# MSS_RCM_MSS_RCM_53208000h register map
Vendor: Texas Instruments
Registers are 32-bit, read-write, reset 0x0 unless marked. A register's access mark holds for its fields unless they carry their own. Offsets are as the file gives them; [hi:lo] are bit positions; {n}, {i} and the like mark numbered series.

## MSS_RCM (part 2 of 2)
0x10 MSS_RCM_R5SS0_RST_STATUS ro reset 0x3 — R5SS Reset Cause Status register of corresponding R5SS.
  [10:0] R5SS0_RST_STATUS_CAUSE — Has the status because of which reset has happened. Bit0: POR ResetBit1: Warm Reset [ALso set during POR Reset]Bit2: CR5SS0 STC ResetBit3 Reset for CORE0 and MSS_CORE00_VIM using MSS_RCM::MSS_CR5SSA0_RST_CTRLBit4: Reset for CORE1 and MSS_CORE10_VIM using MSS_RCM::MSS_CR5SSB0_RST_CTRLBit5: Reset for CORE0 only using MSS_RCM::MSS_CORE00_RST_CTRLBit6: Reset for CORE1 only using using MSS_RCM::MSS_CORE10_RST_CTRLBit7: Reset for CORE0 and MSS_CORE00_VIM caused because of reset request by debugger in CORE00 Bit8: Reset for CORE10 and MSS_CORE10_VIM caused because of reset request by debugger in CORE10Bit9: Reset for CR5SS0 by the RESET FSM using MSS_CTRL::R5SS0_CONTROL_RESET_FSM_TRIGGER Bit10 : Reset for CR5SS0 using MSS_RCM.R5SS0_POR_RST_CTRL
0x20 MSS_RCM_R5SS0_RST_CAUSE_CLR — R5SS Reset Cause Clear register of corresponding R5SS.
  [2:0] R5SS0_RST_CAUSE_CLR_CLR — Has the status because of which reset has happened. Bit0: POR ResetBit1: Warm Reset [ALso set during POR Reset]Bit2: CR5SS1 STC ResetBit3 Reset for CORE0 and MSS_CORE00_VIM using MSS_RCM::MSS_CR5SSA0_RST_CTRLBit4: Reset for CORE1 and MSS_CORE10_VIM using MSS_RCM::MSS_CR5SSB0_RST_CTRLBit5: Reset for CORE0 only using MSS_RCM::MSS_CORE00_RST_CTRLBit6: Reset for CORE1 only using using MSS_RCM::MSS_CORE10_RST_CTRLBit7: Reset for CORE0 and MSS_CORE00_VIM caused because of reset request by debugger in CORE00 Bit8: Reset for CORE10 and MSS_CORE10_VIM caused because of reset request by debugger in CORE10Bit9: Reset for CR5SS0 by the RESET FSM using MSS_CTRL::R5SS0_CONTROL_RESET_FSM_TRIGGER Bit10 : Reset for CR5SS1 using MSS_RCM.R5SS0_POR_RST_CTRL
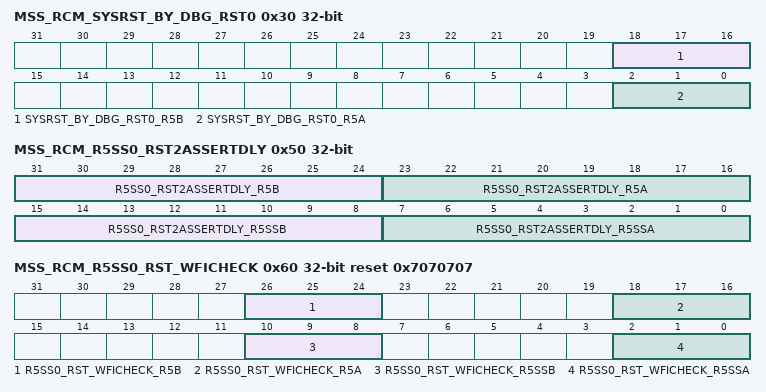
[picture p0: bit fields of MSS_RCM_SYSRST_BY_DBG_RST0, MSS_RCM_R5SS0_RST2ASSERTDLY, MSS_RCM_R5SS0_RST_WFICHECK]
0x30 MSS_RCM_SYSRST_BY_DBG_RST0 — This register enables Core debug reset request to propogate to RCM.
  [18:16] SYSRST_BY_DBG_RST0_R5B — Writing 3'b111 will block debug reset request from CORE1 toggling reset for CORE1 of respective R5SS
  [2:0] SYSRST_BY_DBG_RST0_R5A — Writing 3'b111 will block debug reset request from CORE0 toggling reset for CORE0 of respective R5SS
0x40 MSS_RCM_RST_ASSERDLY0 reset 0xF — This register controls the reset duration of the corrseponding R5SS.
  [7:0] RST_ASSERDLY0_COMMON — Value decides number of cycles reset should be kept asserted for CR5SS related resets. Programming a value of 0xFF will keep the reset asserted untill a new value other than 0xFF is written to this registerThe actual duration is count + 2 cycles. S/W Recommended value for this is 0x0FThe COUNT is applicable to both CPU cores
0x50 MSS_RCM_R5SS0_RST2ASSERTDLY — This register controls the delay of Reset assertion to the corresponding R5SS.
  [31:24] R5SS0_RST2ASSERTDLY_R5B — Value decides number of cycles to wait before asserting reset for local reset for CORE1
  [23:16] R5SS0_RST2ASSERTDLY_R5A — Value decides number of cycles to wait before asserting reset for local reset for CORE0.
  [15:8] R5SS0_RST2ASSERTDLY_R5SSB — Value decides number of cycles to wait before asserting reset for global reset for CORE1
  [7:0] R5SS0_RST2ASSERTDLY_R5SSA — Value decides number of cycles to wait before asserting reset for global reset for CORE0.
0x60 MSS_RCM_R5SS0_RST_WFICHECK reset 0x7070707 — Enable WFI ceck before R5 Reset is asserted.
  [26:24] R5SS0_RST_WFICHECK_R5B — Writing 3'b000 will disable check for WFI before local reset assertion of CORE0
  [18:16] R5SS0_RST_WFICHECK_R5A — Writing 3'b000 will disable check for WFI before local reset assertion of CORE0
  [10:8] R5SS0_RST_WFICHECK_R5SSB — Writing 3'b000 will disable check for WFI before global reset assertion of CORE1
  [2:0] R5SS0_RST_WFICHECK_R5SSA — Writing 3'b000 will disable check for WFI before global reset assertion of CORE0
0x100 MSS_RCM_MCAN0_CLK_SRC_SEL — Clock Source selection Register for corresponding Root clock.
  [11:0] MCAN0_CLK_SRC_SEL_CLKSRCSEL — Select line for selecting source clock for QSPI.Data should be loaded as multibit. For example: if '0x5' should be selected then '0x555' should be configured to the register. Use the following values for selecting clock source-0x000 - WUCPUCLK0x111 - EXT_REFCLK0x222 - SYS_CLK0x333 - DPLL_PER_HSDIV0_CLKOUT10x444 - DPLL_CORE_HSDIV0_CLKOUT00x555 - RCCLK10M0x666 - XTALCLK0x777 - RCCLK10M
0x104 MSS_RCM_MCAN1_CLK_SRC_SEL — Clock Source selection Register for corresponding Root clock.
  [11:0] MCAN1_CLK_SRC_SEL_CLKSRCSEL — Select line for selecting source clock for QSPI.Data should be loaded as multibit. For example: if '0x5' should be selected then '0x555' should be configured to the register. Use the following values for selecting clock source-0x000 - WUCPUCLK0x111 - EXT_REFCLK0x222 - SYS_CLK0x333 - DPLL_PER_HSDIV0_CLKOUT10x444 - DPLL_CORE_HSDIV0_CLKOUT00x555 - RCCLK10M0x666 - XTALCLK0x777 - RCCLK10M
{0x140+4i} MSS_RCM_RTI{i}_CLK_SRC_SEL (i=0..3)
  [11:0] RTI{i}_CLK_SRC_SEL_CLKSRCSEL — Select line for selecting source clock for Corresponding RTI.Data should be loaded as multibit. For example: if '0x5' should be selected then '0x555' should be configured to the register. Use the following values to select clk src- 0x000 - WUCPUCLK0x111 - EXT_REFCLK0x222 - SYS_CLK0x333 - DPLL_PER_HSDIV0_CLKOUT00x444 - DPLL_CORE_HSDIV0_CLKOUT10x555 - RCCLK10M0x666 - DPLL_ETH_HSDIV0_CLKOUT00x777 - CTPS_GENF0
{0x180+4i} MSS_RCM_MCSPI{i}_CLK_SRC_SEL (i=0..3)
  [11:0] MCSPI{i}_CLK_SRC_SEL_CLKSRCSEL — Select line for selecting source clock for Corresponding SPI.Data should be loaded as multibit. For example: if '0x5' should be selected then '0x555' should be configured to the register.Use the following values to select clk src-0x000 - WUCPUCLK0x111 - EXT_REFCLK0x222 - SYS_CLK0x333 - DPLL_PER_HSDIV0_CLKOUT00x444 - DPLL_CORE_HSDIV0_CLKOUT00x555 - RCCLK10M0x666 - XTALCLK0x777 - RCCLK10M
0x1C0 MSS_RCM_WDT0_CLK_SRC_SEL
  [11:0] WDT0_CLK_SRC_SEL_CLKSRCSEL — Select line for selecting source clock for WDT.Data should be loaded as multibit. For example: if '0x5' should be selected then '0x555' should be configured to the register.Use the following values to select clk src-0x000 - WUCPUCLK0x111 - RCCLK10M0x222 - SYS_CLK0x333 - DPLL_PER_HSDIV0_CLKOUT00x444 - DPLL_CORE_HSDIV0_CLKOUT10x555 - RCCLK10M0x666 - XTALCLK0x777 - RCCLK32K
0x1C4 MSS_RCM_WDT1_CLK_SRC_SEL
  [11:0] WDT1_CLK_SRC_SEL_CLKSRCSEL — Select line for selecting source clock for WDT.Data should be loaded as multibit. For example: if '0x5' should be selected then '0x555' should be configured to the register.Use the following values to select clk src-0x000 - WUCPUCLK0x111 - RCCLK10M0x222 - SYS_CLK0x333 - DPLL_PER_HSDIV0_CLKOUT00x444 - DPLL_CORE_HSDIV0_CLKOUT10x555 - RCCLK10M0x666 - XTALCLK0x777 - RCCLK32K
0x1E0 MSS_RCM_PRU_ICSS0_UART0_CLK_SRC_SEL
  [11:0] PRU_ICSS0_UART0_CLK_SRC_SEL_CLKSRCSEL — Select line for selecting source clock for ICSSM0_UCLK.Data should be loaded as multibit. For example: if '0x5' should be selected then '0x555' should be configured to the register.Use the following values to select clk src-0x000 - WUCPUCLK0x111 - EXT_REFCLK0x222 - SYS_CLK0x333 - DPLL_PER_HSDIV0_CLKOUT00x444 - DPLL_CORE_HSDIV0_CLKOUT00x555 - RCCLK10M0x666 - XTALCLK0x777 - DPLL_PER_HSDIV0_CLKOUT2
0x1E4 MSS_RCM_PRU_ICSS1_UART0_CLK_SRC_SEL
  [11:0] PRU_ICSS1_UART0_CLK_SRC_SEL_CLKSRCSEL — Select line for selecting source clock for ICSSM0_UCLK.Data should be loaded as multibit. For example: if '0x5' should be selected then '0x555' should be configured to the register.Use the following values to select clk src-0x000 - WUCPUCLK0x111 - EXT_REFCLK0x222 - SYS_CLK0x333 - DPLL_PER_HSDIV0_CLKOUT00x444 - DPLL_CORE_HSDIV0_CLKOUT00x555 - RCCLK10M0x666 - XTALCLK0x777 - DPLL_PER_HSDIV0_CLKOUT2
0x1F0 MSS_RCM_OSPI0_CLK_SRC_SEL
  [11:0] OSPI0_CLK_SRC_SEL_CLKSRCSEL — Select line for selecting source clock for OSPI.Data should be loaded as multibit. For example: if '0x5' should be selected then '0x555' should be configured to the register.Use the following values to select clk src-0x000 - WUCPUCLK0x111 - EXT_REFCLK0x222 - SYS_CLK0x333 - DPLL_PER_HSDIV0_CLKOUT00x444 - DPLL_ETH_HSDIV0_CLKOUT20x555 - RCCLK10M0x666 - DPLL_CORE_HSDIV0_CLKOUT30x777 - DPLL_PER_HSDIV0_CLKOUT3
0x1F4 MSS_RCM_OSPI1_CLK_SRC_SEL
  [11:0] OSPI1_CLK_SRC_SEL_CLKSRCSEL — Select line for selecting source clock for OSPI.Data should be loaded as multibit. For example: if '0x5' should be selected then '0x555' should be configured to the register.Use the following values to select clk src-0x000 - WUCPUCLK0x111 - EXT_REFCLK0x222 - SYS_CLK0x333 - DPLL_PER_HSDIV0_CLKOUT00x444 - DPLL_ETH_HSDIV0_CLKOUT20x555 - RCCLK10M0x666 - DPLL_CORE_HSDIV0_CLKOUT30x777 - DPLL_PER_HSDIV0_CLKOUT3
0x1F8 MSS_RCM_CONTROLSS_PLL_CLK_SRC_SEL
  [11:0] CONTROLSS_PLL_CLK_SRC_SEL_CLKSRCSEL — Select line for selecting source clock for CONTROLSS_PLL.Data should be loaded as multibit. For example: if '0x5' should be selected then '0x555' should be configured to the register.Use the following values to select clk src-0x000 - WUCPUCLK0x111 - EXT_REFCLK0x222 - DPLL_CORE_HSDIV0_CLKOUT20x333 - DPLL_PER_HSDIV0_CLKOUT00x444 - DPLL_CORE_HSDIV0_CLKOUT00x555 - RCCLK10M0x666 - XTALCLK0x777 - RCCLK10M
0x1FC MSS_RCM_CPTS_CLK_SRC_SEL
  [11:0] CPTS_CLK_SRC_SEL_CLKSRCSEL — Select line for selecting source clock for CPTS.Data should be loaded as multibit. For example: if '0x5' should be selected then '0x555' should be configured to the register.Use the following values to select clk src-0x000 - WUCPUCLK0x111 - EXT_REFCLK0x222 - SYS_CLK0x333 - DPLL_CORE_HSDIV0_CLKOUT10x444 - DPLL_ETH_HSDIV0_CLKOUT00x555 - RCCLK10M0x666 - XTALCLK0x777 - DPLL_PER_HSDIV0_CLKOUT1
0x200 MSS_RCM_GPMC_CLK_SRC_SEL
  [11:0] GPMC_CLK_SRC_SEL_CLKSRCSEL — Select line for selecting source clock for GPMC. Data should be loaded as multibit. For example: if '0x5' should be selected then '0x555' should be configured to the register.Use the following values to select clk src-0x000 - WUCPUCLK0x111 - EXT_REFCLK0x222 - SYS_CLK0x333 - DPLL_PER_HSDIV0_CLKOUT00x444 - DPLL_CORE_HSDIV0_CLKOUT00x555 - RCCLK10M0x666 - XTALCLK0x777 - RCCLK10M
0x204 MSS_RCM_MMC0_CLK_SRC_SEL
  [11:0] MMC0_CLK_SRC_SEL_CLKSRCSEL — Select line for selecting source clock for MMCSD.Data should be loaded as multibit. For example: if '0x5' should be selected then '0x555' should be configured to the register.Use the following values to select clk src-0x000 - WUCPUCLK0x111 - EXT_REFCLK0x222 - SYS_CLK0x333 - DPLL_PER_HSDIV0_CLKOUT00x444 - DPLL_CORE_HSDIV0_CLKOUT00x555 - RCCLK10M0x666 - XTALCLK0x777 - RCCLK10M
0x220 MSS_RCM_CPSW_5_50_250_CLK_MUX_CTRL
  [11:0] CPSW_5_50_250_CLK_MUX_CTRL_CLKSRCSEL — Select line for selecting source clock for corresponding CPSW.Data should be loaded as multibit. For example: if '0x5' should be selected then '0x555' should be configured to the register.Use the following values to select clk src-0x000 - WUCPUCLK0x000 - WUCPUCLK0x111 - XTALCLK0x222 - SYS_CLK0x333 - DPLL_CORE_HSDIV0_CLKOUT10x444 - DPLL_ETH_HSDIV0_CLKOUT00x555 - RCCLK10M0x666 - EXT_REFCLK0x777 - DPLL_PER_HSDIV0_CLKOUT1
0x224 MSS_RCM_I2C_CLK_SRC_SEL
  [11:0] I2C_CLK_SRC_SEL_CLKSRCSEL — Select line for selecting source clock for I2C.Data should be loaded as multibit. For example: if '0x5' should be selected then '0x555' should be configured to the register.Use the following values to select clk src-0x000 - WUCPUCLK0x111 - EXT_REFCLK0x222 - SYS_CLK0x333 - DPLL_PER_HSDIV0_CLKOUT00x444 - DPLL_CORE_HSDIV0_CLKOUT00x555 - RCCLK10M0x666 - XTALCLK0x777 - RCCLK10M
{0x264+4i} MSS_RCM_LIN{i}_UART{i}_CLK_SRC_SEL (i=0..5)
  [11:0] LIN{i}_UART{i}_CLK_SRC_SEL_CLKSRCSEL — Select line for selecting source clock for corresponding UART and LIN.Data should be loaded as multibit. For example: if '0x5' should be selected then '0x555' should be configured to the register.Use the following values to select clk src-0x000 - WUCPUCLK0x111 - EXT_REFCLK0x222 - SYS_CLK0x333 - DPLL_PER_HSDIV0_CLKOUT00x444 - DPLL_CORE_HSDIV0_CLKOUT00x555 - RCCLK10M0x666 - XTALCLK0x777 - DPLL_PER_HSDIV0_CLKOUT2
0x2E4 MSS_RCM_PRU_ICSS0_CORE_CLK_SRC_SEL
  [11:0] PRU_ICSS0_CORE_CLK_SRC_SEL_CLKSRCSEL — Select line for selecting source clock for ICSSM0_CORE.Data should be loaded as multibit. For example: if '0x5' should be selected then '0x555' should be configured to the register.Use the following values to select clk src-0x000 - WUCPUCLK0x111 - EXT_REFCLK0x222 - SYS_CLK0x333 - DPLL_ETH_HSDIV0_CLKOUT00x444 - DPLL_CORE_HSDIV0_CLKOUT10x555 - RCCLK10M0x666 - XTALCLK0x777 - DPLL_PER_HSDIV0_CLKOUT1
0x2E8 MSS_RCM_PRU_ICSS1_CORE_CLK_SRC_SEL
  [11:0] PRU_ICSS1_CORE_CLK_SRC_SEL_CLKSRCSEL — Select line for selecting source clock for ICSSM0_CORE.Data should be loaded as multibit. For example: if '0x5' should be selected then '0x555' should be configured to the register.Use the following values to select clk src-0x000 - WUCPUCLK0x111 - EXT_REFCLK0x222 - SYS_CLK0x333 - DPLL_ETH_HSDIV0_CLKOUT00x444 - DPLL_CORE_HSDIV0_CLKOUT10x555 - RCCLK10M0x666 - XTALCLK0x777 - DPLL_PER_HSDIV0_CLKOUT1
0x300 MSS_RCM_MCAN0_CLK_DIV_VAL
  [11:0] MCAN0_CLK_DIV_VAL_CLKDIVR — Divider value corresponding MCAN selected clock.To set the divider value of [n+1] configure the register to '0xnnn'.Data should be loaded as multibit. For example: if divider value of '0x9' is required then '0x888' should be configured to the register.
0x304 MSS_RCM_MCAN1_CLK_DIV_VAL
  [11:0] MCAN1_CLK_DIV_VAL_CLKDIVR — Divider value corresponding MCAN selected clock.To set the divider value of [n+1] configure the register to '0xnnn'.Data should be loaded as multibit. For example: if divider value of '0x9' is required then '0x888' should be configured to the register.
{0x340+4i} MSS_RCM_RTI{i}_CLK_DIV_VAL (i=0..3)
  [11:0] RTI{i}_CLK_DIV_VAL_CLKDIVR — Divider value Corresponding RTI selected clock.To set the divider value of [n+1] configure the register to '0xnnn'.Data should be loaded as multibit. For example: if divider value of '0x9' is required then '0x888' should be configured to the register.
{0x380+4i} MSS_RCM_MCSPI{i}_CLK_DIV_VAL (i=0..3)
  [11:0] MCSPI{i}_CLK_DIV_VAL_CLKDIVR — Divider value Corresponding SPI selected clock.To set the divider value of [n+1] configure the register to '0xnnn'.Data should be loaded as multibit. For example: if divider value of '0x9' is required then '0x888' should be configured to the register.
0x3C0 MSS_RCM_WDT0_CLK_DIV_VAL
  [11:0] WDT0_CLK_DIV_VAL_CLKDIVR — Divider value WDT selected clock.To set the divider value of [n+1] configure the register to '0xnnn'.Data should be loaded as multibit. For example: if divider value of '0x9' is required then '0x888' should be configured to the register.
0x3C4 MSS_RCM_WDT1_CLK_DIV_VAL
  [11:0] WDT1_CLK_DIV_VAL_CLKDIVR — Divider value WDT selected clock.To set the divider value of [n+1] configure the register to '0xnnn'.Data should be loaded as multibit. For example: if divider value of '0x9' is required then '0x888' should be configured to the register.
0x3E0 MSS_RCM_PRU_ICSS0_UART_CLK_DIV_VAL
  [11:0] PRU_ICSS0_UART_CLK_DIV_VAL_CLKDIVR — Divider value ICSSM0_UCLK selected clock.To set the divider value of [n+1] configure the register to '0xnnn'.Data should be loaded as multibit. For example: if divider value of '0x9' is required then '0x888' should be configured to the register.
0x3E4 MSS_RCM_PRU_ICSS1_UART_CLK_DIV_VAL
  [11:0] PRU_ICSS1_UART_CLK_DIV_VAL_CLKDIVR — Divider value ICSSM0_UCLK selected clock.To set the divider value of [n+1] configure the register to '0xnnn'.Data should be loaded as multibit. For example: if divider value of '0x9' is required then '0x888' should be configured to the register.
0x3F0 MSS_RCM_OSPI0_CLK_DIV_VAL
  [11:0] OSPI0_CLK_DIV_VAL_CLKDIVR — Divider value OSPI selected clock.To set the divider value of [n+1] configure the register to '0xnnn'.Data should be loaded as multibit. For example: if divider value of '0x9' is required then '0x888' should be configured to the register.
0x3F4 MSS_RCM_OSPI1_CLK_DIV_VAL
  [11:0] OSPI1_CLK_DIV_VAL_CLKDIVR — Divider value OSPI selected clock.To set the divider value of [n+1] configure the register to '0xnnn'.Data should be loaded as multibit. For example: if divider value of '0x9' is required then '0x888' should be configured to the register.
0x3F8 MSS_RCM_CONTROLSS_PLL_CLK_DIV_VAL — CONTROLSS_PLL_CLK Divider Value for Control subsystem.
  [11:0] CONTROLSS_PLL_CLK_DIV_VAL_CLKDIVR — Divider value CONTROLSS_PLL selected clock.To set the divider value of [n+1] configure the register to '0xnnn'.Data should be loaded as multibit. For example: if divider value of '0x9' is required then '0x888' should be configured to the register.
0x3FC MSS_RCM_CPTS_CLK_DIV_VAL
  [11:0] CPTS_CLK_DIV_VAL_CLKDIVR — Divider value CPTS selected clock.To set the divider value of [n+1] configure the register to '0xnnn'.Data should be loaded as multibit. For example: if divider value of '0x9' is required then '0x888' should be configured to the register.
0x400 MSS_RCM_GPMC_CLK_DIV_VAL
  [11:0] GPMC_CLK_DIV_VAL_CLKDIVR — Divider value GPMC selected clock.To set the divider value of [n+1] configure the register to '0xnnn'.Data should be loaded as multibit. For example: if divider value of '0x9' is required then '0x888' should be configured to the register.
0x404 MSS_RCM_MMC0_CLK_DIV_VAL
  [11:0] MMC0_CLK_DIV_VAL_CLKDIVR — Divider value MMCSD selected clock.To set the divider value of [n+1] configure the register to '0xnnn'.Data should be loaded as multibit. For example: if divider value of '0x9' is required then '0x888' should be configured to the register.
0x408 MSS_RCM_MSS_ELM_CLK_DIV_VAL reset 0x333 — ELM CLK Divider Value.
  [11:0] MSS_ELM_CLK_DIV_VAL_CLKDIVR — Divider value ELM clock.To set the divider value of [n+1] configure the register to '0xnnn'.Data should be loaded as multibit. For example: if divider value of '0x9' is required then '0x888' should be configured to the register.
0x40C MSS_RCM_RGMII_5_CLK_DIV_VAL reset 0x636363 — RGMII 5 CLK Divider Value.
  [23:0] RGMII_5_CLK_DIV_VAL_CLKDIVR — Divider value MII10 selected clock.To set the divider value of [n+1] configure the register to '0xnnn'.Data should be loaded as multibit. For example: if divider value of '0x9' is required then '0x888' should be configured to the register.
0x410 MSS_RCM_RGMII_50_CLK_DIV_VAL reset 0x999 — RGMII 50 CLK Divider Value.
  [11:0] RGMII_50_CLK_DIV_VAL_CLKDIVR — Divider value MII100 selected clock.To set the divider value of [n+1] configure the register to '0xnnn'.Data should be loaded as multibit. For example: if divider value of '0x9' is required then '0x888' should be configured to the register.
0x414 MSS_RCM_RGMII_250_CLK_DIV_VAL reset 0x111 — RGMII 250 CLK Divider Value.
  [11:0] RGMII_250_CLK_DIV_VAL_CLKDIVR — Divider value RGMII selected clock.To set the divider value of [n+1] configure the register to '0xnnn'.Data should be loaded as multibit. For example: if divider value of '0x9' is required then '0x888' should be configured to the register.
0x418 MSS_RCM_XTAL_32K_CLK_DIV_VAL reset 0x30CC330C — XTAL 32K CLK Divider Value for MMC.
  [29:0] XTAL_32K_CLK_DIV_VAL_CLKDIVR — Divider value for XTAL_32K clock. To set the divider value of [n+1] configure the register to value of '0xnnn'.Data should be loaded as multibit. For example: if divider value of '0x30C' is required then register should be configured as follows -bits[9:0] = 0x30Cbits[19:10] = 0x30Cbits[29:20] = 0x30CThis configures the register to 0x30CC330C
0x41C MSS_RCM_XTAL_TEMPSENSE_32K_CLK_DIV_VAL reset 0x30CC330C — XTAL 32K CLK Divider Value for Temp Sensor.
  [29:0] XTAL_TEMPSENSE_32K_CLK_DIV_VAL_CLKDIVR — Divider value for XTAL_32K clock. To set the divider value of [n+1] configure the register to value of '0xnnn'.Data should be loaded as multibit. For example: if divider value of '0x30C' is required then register should be configured as follows -bits[9:0] = 0x30Cbits[19:10] = 0x30Cbits[29:20] = 0x30CThis configures the register to 0x30CC330C
0x424 MSS_RCM_I2C_CLK_DIV_VAL
  [11:0] I2C_CLK_DIV_VAL_CLKDIVR — Divider value I2C selected clock.To set the divider value of [n+1] configure the register to '0xnnn'.Data should be loaded as multibit. For example: if divider value of '0x9' is required then '0x888' should be configured to the register.
{0x464+4i} MSS_RCM_LIN{i}_UART{i}_CLK_DIV_VAL (i=0..5)
  [11:0] LIN{i}_UART{i}_CLK_DIV_VAL_CLKDIVR — Divider value for corresponding UART and LIN selected clock.To set the divider value of [n+1] configure the register to '0xnnn'.Data should be loaded as multibit. For example: if divider value of '0x9' is required then '0x888' should be configured to the register.
0x4E4 MSS_RCM_PRU_ICSS0_CORE_CLK_DIV_VAL
  [11:0] PRU_ICSS0_CORE_CLK_DIV_VAL_CLKDIVR — Divider value ICSSM0_UCLK selected clock.To set the divider value of [n+1] configure the register to '0xnnn'.Data should be loaded as multibit. For example: if divider value of '0x9' is required then '0x888' should be configured to the register.
0x4E8 MSS_RCM_PRU_ICSS1_CORE_CLK_DIV_VAL
  [11:0] PRU_ICSS1_CORE_CLK_DIV_VAL_CLKDIVR — Divider value ICSSM0_UCLK selected clock.To set the divider value of [n+1] configure the register to '0xnnn'.Data should be loaded as multibit. For example: if divider value of '0x9' is required then '0x888' should be configured to the register.
0x500 MSS_RCM_MCAN0_CLK_GATE
  [2:0] MCAN0_CLK_GATE_GATED — Writing 3'b111 will gate clock for corresponding MCAN
0x504 MSS_RCM_MCAN1_CLK_GATE
  [2:0] MCAN1_CLK_GATE_GATED — Writing 3'b111 will gate clock for corresponding MCAN
{0x540+4i} MSS_RCM_RTI{i}_CLK_GATE (i=0..3)
  [2:0] RTI{i}_CLK_GATE_GATED — Writing 3'b111 will gate clock for Corresponding RTI
{0x580+4i} MSS_RCM_MCSPI{i}_CLK_GATE (i=0..3)
  [2:0] MCSPI{i}_CLK_GATE_GATED — Writing 3'b111 will gate clock for Corresponding SPI
0x5C0 MSS_RCM_WDT0_CLK_GATE
  [2:0] WDT0_CLK_GATE_GATED — Writing 3'b111 will gate clock for WDT
0x5C4 MSS_RCM_WDT1_CLK_GATE
  [2:0] WDT1_CLK_GATE_GATED — Writing 3'b111 will gate clock for WDT
0x5E0 MSS_RCM_PRU_ICSS0_UART_CLK_GATE
  [2:0] PRU_ICSS0_UART_CLK_GATE_GATED — Writing 3'b111 will gate clock for ICSSM0_UCLK
0x5E4 MSS_RCM_PRU_ICSS1_UART_CLK_GATE
  [2:0] PRU_ICSS1_UART_CLK_GATE_GATED — Writing 3'b111 will gate clock for ICSSM0_UCLK
0x5F0 MSS_RCM_OSPI0_CLK_GATE
  [2:0] OSPI0_CLK_GATE_GATED — Writing 3'b111 will gate clock for OSPI
0x5F4 MSS_RCM_OSPI1_CLK_GATE
  [2:0] OSPI1_CLK_GATE_GATED — Writing 3'b111 will gate clock for OSPI
0x5F8 MSS_RCM_CONTROLSS_PLL_CLK_GATE
  [2:0] CONTROLSS_PLL_CLK_GATE_GATED — Writing 3'b111 will gate clock for CONTROLSS_PLL
0x5FC MSS_RCM_CPTS_CLK_GATE
  [2:0] CPTS_CLK_GATE_GATED — Writing 3'b111 will gate clock for CPTS
0x600 MSS_RCM_GPMC_CLK_GATE
  [2:0] GPMC_CLK_GATE_GATED — Writing 3'b111 will gate clock for GPMC
0x604 MSS_RCM_MMC0_CLK_GATE
  [2:0] MMC0_CLK_GATE_GATED — Writing 3'b111 will gate clock for MMCSD
0x608 MSS_RCM_MSS_ELM_CLK_GATE
  [2:0] MSS_ELM_CLK_GATE_GATED — Writing 3'b111 will gate clock for ELM
0x60C MSS_RCM_RGMII_5_CLK_GATE
  [2:0] RGMII_5_CLK_GATE_GATED — Writing 3'b111 will gate clock for MII10
0x610 MSS_RCM_RGMII_50_CLK_GATE
  [2:0] RGMII_50_CLK_GATE_GATED — Writing 3'b111 will gate clock for MII100
0x614 MSS_RCM_RGMII_250_CLK_GATE
  [2:0] RGMII_250_CLK_GATE_GATED — Writing 3'b111 will gate clock for RGMII
0x618 MSS_RCM_MMC0_32K_CLK_GATE
  [2:0] MMC0_32K_CLK_GATE_GATED — Writing 3'b111 will gate clock for MMCSD_32K
0x61C MSS_RCM_TEMPSENSE_32K_CLK_GATE
  [2:0] TEMPSENSE_32K_CLK_GATE_GATED — Writing 3'b111 will gate clock for TEMPSENSE_32K
0x620 MSS_RCM_CPSW_CLK_GATE
  [2:0] CPSW_CLK_GATE_GATED — Writing 3'b111 will gate clock for CPSW CPPI
{0x624+4i} MSS_RCM_I2C{i}_CLK_GATE (i=0..2)
  [2:0] I2C{i}_CLK_GATE_GATED — Writing 3'b111 will gate clock for I2C
{0x664+4i} MSS_RCM_LIN{i}_CLK_GATE (i=0..2)
  [2:0] LIN{i}_CLK_GATE_GATED — Writing 3'b111 will gate clock for SPIB
{0x6A4+4i} MSS_RCM_UART{i}_CLK_GATE (i=0..5)
  [2:0] UART{i}_CLK_GATE_GATED — Writing 3'b111 will gate clock for corresponding UART
0x6E4 MSS_RCM_MSS_PRU_ICSS0_CORE_CLK_GATE
  [2:0] MSS_PRU_ICSS0_CORE_CLK_GATE_GATED — Writing 3'b111 will gate clock for ICSSM0_CORE
0x6E8 MSS_RCM_MSS_PRU_ICSS1_CORE_CLK_GATE
  [2:0] MSS_PRU_ICSS1_CORE_CLK_GATE_GATED — Writing 3'b111 will gate clock for ICSSM0_CORE
0x700 MSS_RCM_R5SS0_CORE0_GATE — Clock gating for individual CPU core.
  [2:0] R5SS0_CORE0_GATE_CLKGATE — Writing 3'b111 will gate clock to CORE0 related peripherals inside Cortexr5ss
0x710 MSS_RCM_R5SS0_CORE1_GATE — Clock gating for individual CPU core.
  [2:0] R5SS0_CORE1_GATE_CLKGATE — Writing 3'b111 will gate clock to CORE1 related peripherals inside Cortexr5ss
0x720 MSS_RCM_PRU_ICSS0_IEP_CLK_GATE
  [2:0] PRU_ICSS0_IEP_CLK_GATE_GATED — Writing 3'b111 will gate clock for ICSSM0_IEP
0x724 MSS_RCM_PRU_ICSS1_IEP_CLK_GATE
  [2:0] PRU_ICSS1_IEP_CLK_GATE_GATED — Writing 3'b111 will gate clock for ICSSM0_IEP
0x730 MSS_RCM_MSS_PRU_ICSS0_SYS_CLK_GATE
  [2:0] MSS_PRU_ICSS0_SYS_CLK_GATE_GATED — Writing 3'b111 will gate clock for ICSSM0_SYS
0x734 MSS_RCM_MSS_PRU_ICSS1_SYS_CLK_GATE
  [2:0] MSS_PRU_ICSS1_SYS_CLK_GATE_GATED — Writing 3'b111 will gate clock for ICSSM0_SYS
0x740 MSS_RCM_USB_CLK_GATE
  [2:0] USB_CLK_GATE_GATED — Writing 3'b111 will gate clock for USB
0x744 MSS_RCM_USB_WKUP_CLK_GATE — Clock gating for usb wakeup clock.
  [2:0] USB_WKUP_CLK_GATE_GATED — Writing 3'b111 will gate clock for USB_WKUP CLK
0x748 MSS_RCM_USB_XTAL_CLK_GATE — Clock gating for usb xtal clock.
  [2:0] USB_XTAL_CLK_GATE_GATED — Writing 3'b111 will gate clock for USB_XTAL CLK
0x800 MSS_RCM_HSM_RTIA_CLK_SRC_SEL
  [11:0] HSM_RTIA_CLK_SRC_SEL_CLKSRCSEL — Select line for selecting source clock for HSM_Corresponding RTI.Data should be loaded as multibit. For example: if '0x5' should be selected then '0x555' should be configured to the register.Use the following values to select clk src-0x000 - WUCPUCLK0x111 - XTALCLK0x222 - SYS_CLK0x333 - DPLL_PER_HSDIV0_CLKOUT00x444 - RCCLK10M0x555 - RCCLK10M0x666 - EXT_REFCLK0x777 - RCCLK32K
